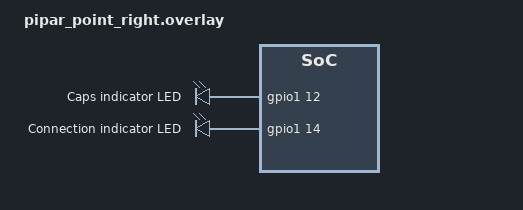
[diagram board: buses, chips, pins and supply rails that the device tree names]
#include "pipar_point_zmk_common.dtsi"

&matrix_transform0 {
    col-offset = <7>;
};

/ {
    indicators {
        compatible = "gpio-leds";
        caps_led: led_caps {
            gpios = <&gpio1 12 GPIO_ACTIVE_HIGH>;
            label = "Caps indicator LED";
        };
        connection_led: led_connection {
            gpios = <&gpio1 14 GPIO_ACTIVE_HIGH>;
            label = "Connection indicator LED";
        };
    };
};

